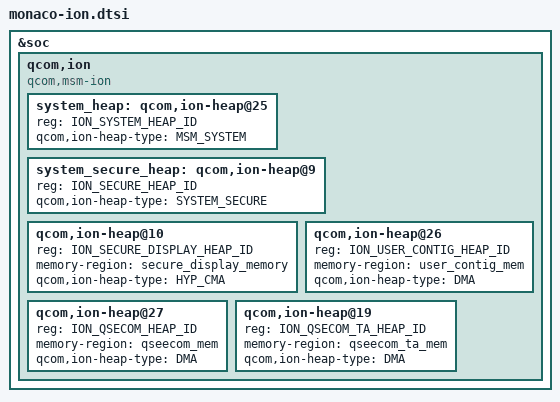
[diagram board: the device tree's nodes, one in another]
#include <dt-bindings/arm/msm/msm_ion_ids.h>
&soc {
	qcom,ion {
		compatible = "qcom,msm-ion";
		#address-cells = <1>;
		#size-cells = <0>;

		system_heap: qcom,ion-heap@25 {
			reg = <ION_SYSTEM_HEAP_ID>;
			qcom,ion-heap-type = "MSM_SYSTEM";
		};

		system_secure_heap: qcom,ion-heap@9 {
			reg = <ION_SECURE_HEAP_ID>;
			qcom,ion-heap-type = "SYSTEM_SECURE";
		};

		qcom,ion-heap@10 { /* SECURE DISPLAY HEAP */
			reg = <ION_SECURE_DISPLAY_HEAP_ID>;
			memory-region = <&secure_display_memory>;
			qcom,ion-heap-type = "HYP_CMA";
		};

		qcom,ion-heap@26 { /* USER CONTIG HEAP */
			reg = <ION_USER_CONTIG_HEAP_ID>;
			memory-region = <&user_contig_mem>;
			qcom,ion-heap-type = "DMA";
		};

		qcom,ion-heap@27 { /* QSEECOM HEAP */
			reg = <ION_QSECOM_HEAP_ID>;
			memory-region = <&qseecom_mem>;
			qcom,ion-heap-type = "DMA";
		};

		qcom,ion-heap@19 { /* QSEECOM HEAP */
			reg = <ION_QSECOM_TA_HEAP_ID>;
			memory-region = <&qseecom_ta_mem>;
			qcom,ion-heap-type = "DMA";
		};
	};
};
